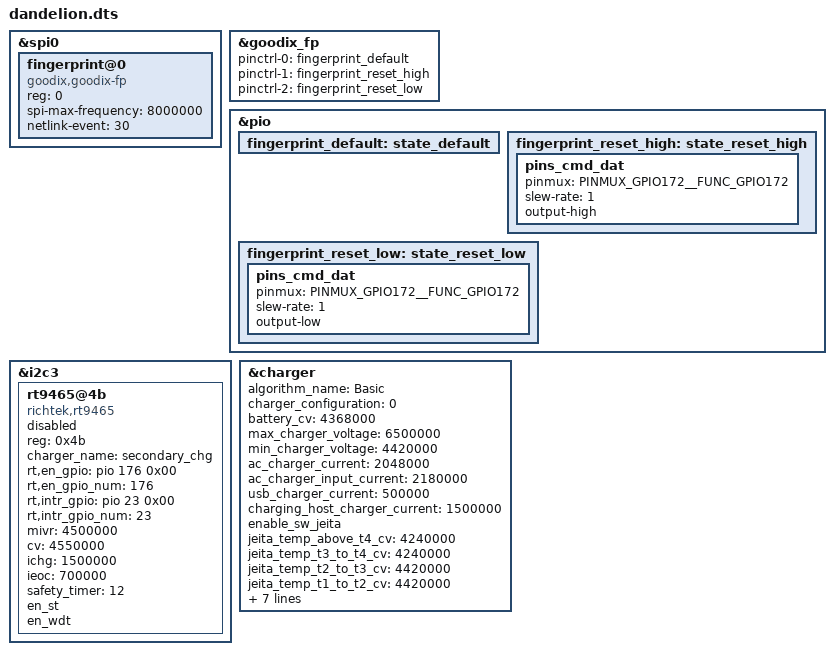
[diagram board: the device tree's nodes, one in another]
/*
 * Copyright (C) 2019 MediaTek Inc.
 * Copyright (C) 2021 XiaoMi, Inc.
 *
 * This program is free software; you can redistribute it and/or modify
 * it under the terms of the GNU General Public License version 2 as
 * published by the Free Software Foundation.
 *
 * This program is distributed in the hope that it will be useful,
 * but WITHOUT ANY WARRANTY; without even the implied warranty of
 * MERCHANTABILITY or FITNESS FOR A PARTICULAR PURPOSE.
 * See http://www.gnu.org/licenses/gpl-2.0.html for more details.
 */

#include "custom_common.dtsi"
#include "touchscreen.dtsi"

/* FINGERPRINT start */
&spi0 {
	#address-cells = <1>;
	#size-cells = <0>;
	fingerprint@0 {
		compatible = "goodix,goodix-fp";
		reg = <0>;
		spi-max-frequency = <8000000>;
		netlink-event = <30>;
		status = "okay";
	};
};

&goodix_fp {
	pinctrl-names = "default", "reset_high", "reset_low";
	pinctrl-0 = <&fingerprint_default>;
	pinctrl-1 = <&fingerprint_reset_high>;
	pinctrl-2 = <&fingerprint_reset_low>;
	status = "okay";
};

&pio {
	fingerprint_default: state_default {
	};
	fingerprint_reset_high: state_reset_high {
		pins_cmd_dat {
			pinmux = <PINMUX_GPIO172__FUNC_GPIO172>;
			slew-rate = <1>;
			output-high;
		};
	};
	fingerprint_reset_low: state_reset_low {
		pins_cmd_dat {
			pinmux = <PINMUX_GPIO172__FUNC_GPIO172>;
			slew-rate = <1>;
			output-low;
		};
	};
};
/* FINGERPRINT end */

/* CHARGER start */

&i2c3 {
	rt9465@4b {
		compatible = "richtek,rt9465";
		reg = <0x4b>;
		interrupt-names = "wdtmri";
		status = "okay";
		charger_name = "secondary_chg";

		rt,en_gpio = <&pio 176 0x00>; /* GPIO */
		rt,en_gpio_num = <176>; /* direct defined GPIO num */
		rt,intr_gpio = <&pio 23 0x00>; /* GPIO */
		rt,intr_gpio_num = <23>; /* direct defined GPIO num */

		mivr = <4500000>;	/* uV */
		cv = <4550000>;		/* uA */
		ichg = <1500000>;	/* uA */
		ieoc = <700000>;	/* uA */
		safety_timer = <12>;		/* hour */
		en_st;
		en_wdt;
	};
};

&charger {
    algorithm_name = "Basic";
    charger_configuration = <0>; /* single charger */

    battery_cv = <4368000>;
    max_charger_voltage = <6500000>;
    min_charger_voltage = <4420000>;

    ac_charger_current = <2048000>;
    ac_charger_input_current = <2180000>;
    usb_charger_current = <500000>;
    charging_host_charger_current = <1500000>;

    enable_sw_jeita;
    jeita_temp_above_t4_cv = <4240000>;
    jeita_temp_t3_to_t4_cv = <4240000>;
    jeita_temp_t2_to_t3_cv = <4420000>;
    jeita_temp_t1_to_t2_cv = <4420000>;
    jeita_temp_t0_to_t1_cv = <4420000>;
    jeita_temp_below_t0_cv = <4420000>;

    temp_t4_thres = <60>;
    temp_t3_thres = <50>;
    temp_t2_thres = <15>;
    temp_t1_thres = <10>;
    temp_t0_thres = <0>;
};

/* disable rt9465 */
&i2c3 {
    rt9465@4b {
        status = "disabled";
    };
};

/* CHARGER end */

#include "mediatek/dandelion/cust.dtsi"
